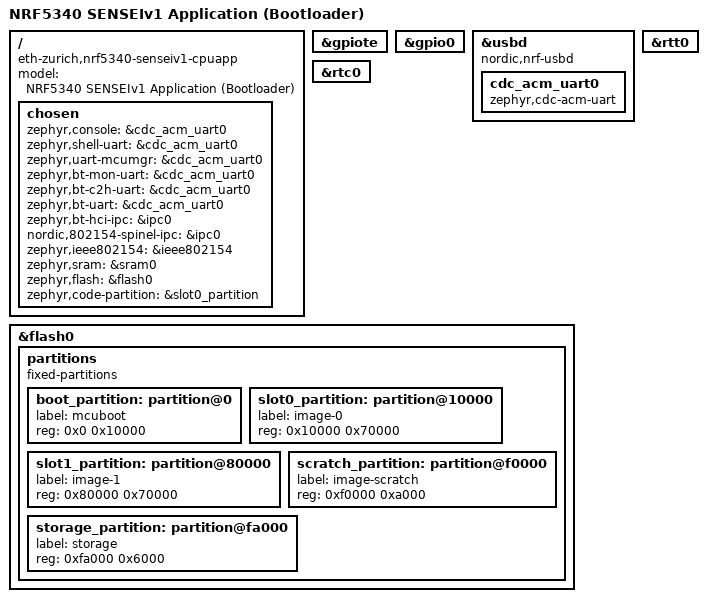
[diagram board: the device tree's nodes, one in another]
// Copyright (c) 2025 ETH Zurich and University of Bologna
// SPDX-License-Identifier: Apache-2.0

/dts-v1/;
#include <nordic/nrf5340_cpuapp_qkaa.dtsi>
#include <zephyr/dt-bindings/input/input-event-codes.h>

/ {
	model = "NRF5340 SENSEIv1 Application (Bootloader)";
	compatible = "eth-zurich,nrf5340-senseiv1-cpuapp";

	chosen {
		zephyr,console = &cdc_acm_uart0;
		zephyr,shell-uart = &cdc_acm_uart0;
		zephyr,uart-mcumgr = &cdc_acm_uart0;
		zephyr,bt-mon-uart = &cdc_acm_uart0;
		zephyr,bt-c2h-uart = &cdc_acm_uart0;
		zephyr,bt-uart = &cdc_acm_uart0;
		zephyr,bt-hci-ipc = &ipc0;
		nordic,802154-spinel-ipc = &ipc0;
		zephyr,ieee802154 = &ieee802154;
		zephyr,sram = &sram0;
		zephyr,flash = &flash0;
		zephyr,code-partition = &slot0_partition;
	};

};

#include "nrf5340_senseiv1_shared.dtsi"

&gpiote {
	status = "okay";
};

&gpio0 {
	status = "okay";
};

zephyr_udc0: &usbd {
	compatible = "nordic,nrf-usbd";
	status = "okay";
	cdc_acm_uart0: cdc_acm_uart0 {
			compatible = "zephyr,cdc-acm-uart";
	};
};


&rtt0 {
    status = "okay";
};

&rtc0 {
	status = "okay";
};


&flash0 {
	partitions {
		compatible = "fixed-partitions";
		#address-cells = <1>;
		#size-cells = <1>;

		boot_partition: partition@0 {
			label = "mcuboot";
			reg = <0x0 0x10000>;
		};
		slot0_partition: partition@10000 {
			label = "image-0";
			reg = <0x10000 0x70000>;
		};
		slot1_partition: partition@80000 {
			label = "image-1";
			reg = <0x80000 0x70000>;
		};
		scratch_partition: partition@f0000 {
			label = "image-scratch";
			reg = <0xf0000 0xa000>;
		};
		storage_partition: partition@fa000 {
			label = "storage";
			reg = <0xfa000 0x6000>;
		};
	};
};


